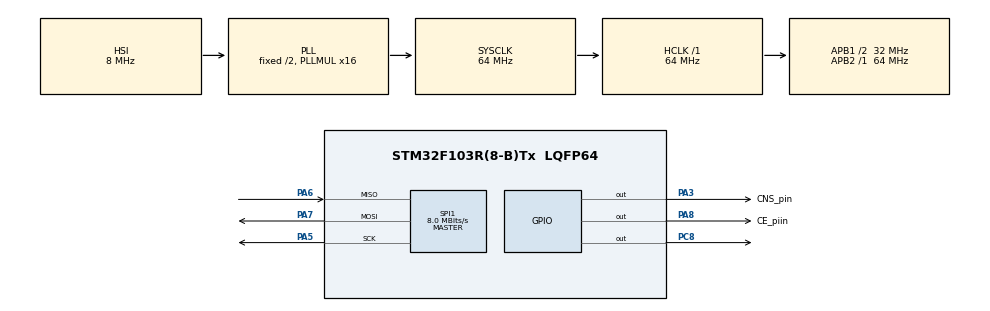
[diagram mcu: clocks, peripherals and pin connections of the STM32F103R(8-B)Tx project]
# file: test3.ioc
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Mcu.Family=STM32F1
Mcu.Name=STM32F103R(8-B)Tx
Mcu.Package=LQFP64
NVIC.PriorityGroup=NVIC_PRIORITYGROUP_4
PA3.GPIO_Label=CNS_pin
PA3.Signal=GPIO_Output
PA5.Mode=Full_Duplex_Master
PA5.Signal=SPI1_SCK
PA6.Mode=Full_Duplex_Master
PA6.Signal=SPI1_MISO
PA7.Mode=Full_Duplex_Master
PA7.Signal=SPI1_MOSI
PA8.GPIO_Label=CE_piin
PA8.Signal=GPIO_Output
PC8.Signal=GPIO_Output
ProjectManager.HeapSize=0x200
ProjectManager.StackSize=0x400
ProjectManager.TargetToolchain=STM32CubeIDE
RCC.AHBFreq_Value=64000000
RCC.APB1CLKDivider=RCC_HCLK_DIV2
RCC.APB1Freq_Value=32000000
RCC.APB1TimFreq_Value=64000000
RCC.APB2Freq_Value=64000000
RCC.APB2TimFreq_Value=64000000
RCC.HCLKFreq_Value=64000000
RCC.PLLMUL=RCC_PLL_MUL16
RCC.RTCClockSelection=RCC_RTCCLKSOURCE_LSE
RCC.SYSCLKFreq_VALUE=64000000
RCC.SYSCLKSource=RCC_SYSCLKSOURCE_PLLCLK
RCC.USBFreq_Value=64000000
SPI1.BaudRatePrescaler=SPI_BAUDRATEPRESCALER_8
SPI1.CalculateBaudRate=8.0 MBits/s
SPI1.Direction=SPI_DIRECTION_2LINES
SPI1.Mode=SPI_MODE_MASTER
SPI1.VirtualType=VM_MASTER
VP_SYS_VS_ND.Mode=No_Debug
board=NUCLEO-F103RB

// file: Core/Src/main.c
/* USER CODE BEGIN Header */
/**
  ******************************************************************************
  * @file           : main.c
  * @brief          : Main program body
  ******************************************************************************
  * @attention
  *
  * Copyright (c) 2025 STMicroelectronics.
  * All rights reserved.
  *
  * This software is licensed under terms that can be found in the LICENSE file
  * in the root directory of this software component.
  * If no LICENSE file comes with this software, it is provided AS-IS.
  *
  ******************************************************************************
  */
/* USER CODE END Header */
#include "main.h"
#include "spi.h"
#include "gpio.h"

/* USER CODE BEGIN Includes */
#include "stdio.h"
#include "string.h"
#include "stm32f1xx_hal.h"
#include "NRF24L01.h"
/* USER CODE END Includes */

void SystemClock_Config(void);

int main(void)
{

  /* MCU Configuration--------------------------------------------------------*/

  /* Reset of all peripherals, Initializes the Flash interface and the Systick. */
  HAL_Init();

  /* Configure the system clock */

  /* Initialize all configured peripherals */
  MX_GPIO_Init();
  MX_SPI1_Init();
  /* USER CODE BEGIN 2 */
  NRF24L01 nrf;
   nrf24_init(&nrf, SPI1, RX, GPIOA, GPIO_PIN_3, GPIOA, GPIO_PIN_8, 32);
   SystemClock_Config();
   LL_Init1msTick(SystemCoreClock);

   uint8_t addr[5] = {'R','x','A','A','A'};
    nrf_RX_address(&nrf, 0, addr);

    uint8_t rx_data[32] = {0};
  /* USER CODE END 2 */

  /* Infinite loop */
  while (1)
  {

    /* USER CODE BEGIN 3 */
	  LL_GPIO_TogglePin(GPIOC, LL_GPIO_PIN_8);
	      LL_mDelay(500);  // 딜레이는 ms 단위
	  }

  /* USER CODE END 3 */
}

void SystemClock_Config(void)
{
  RCC_OscInitTypeDef RCC_OscInitStruct = {0};
  RCC_ClkInitTypeDef RCC_ClkInitStruct = {0};

  /** Initializes the RCC Oscillators according to the specified parameters
  * in the RCC_OscInitTypeDef structure.
  */
  RCC_OscInitStruct.OscillatorType = RCC_OSCILLATORTYPE_HSI;
  RCC_OscInitStruct.HSIState = RCC_HSI_ON;
  RCC_OscInitStruct.HSICalibrationValue = RCC_HSICALIBRATION_DEFAULT;
  RCC_OscInitStruct.PLL.PLLState = RCC_PLL_ON;
  RCC_OscInitStruct.PLL.PLLSource = RCC_PLLSOURCE_HSI_DIV2;
  RCC_OscInitStruct.PLL.PLLMUL = RCC_PLL_MUL16;
  if (HAL_RCC_OscConfig(&RCC_OscInitStruct) != HAL_OK)
  {
    Error_Handler();
  }

  /** Initializes the CPU, AHB and APB buses clocks
  */
  RCC_ClkInitStruct.ClockType = RCC_CLOCKTYPE_HCLK|RCC_CLOCKTYPE_SYSCLK
                              |RCC_CLOCKTYPE_PCLK1|RCC_CLOCKTYPE_PCLK2;
  RCC_ClkInitStruct.SYSCLKSource = RCC_SYSCLKSOURCE_PLLCLK;
  RCC_ClkInitStruct.AHBCLKDivider = RCC_SYSCLK_DIV1;
  RCC_ClkInitStruct.APB1CLKDivider = RCC_HCLK_DIV2;
  RCC_ClkInitStruct.APB2CLKDivider = RCC_HCLK_DIV1;

  if (HAL_RCC_ClockConfig(&RCC_ClkInitStruct, FLASH_LATENCY_2) != HAL_OK)
  {
    Error_Handler();
  }
}

void Error_Handler(void)
{
  __disable_irq();
  while (1)
  {
	  }
}
